# SAM9X60D1G_SOM device description
Architecture: ARM926EJ-S; Family: SAM9; Series: SAM9X6
Registers are 32-bit, read-write, no defined reset value unless marked. A register's access mark holds for its fields unless they carry their own. Offsets are from the block's base; [hi:lo] are bit positions; {n}, {i} and the like mark numbered series.

## AIC — Advanced Interrupt Controller
Instances: AIC 0xFFFFF100
0x00 AIC_SSR — Source Select Register
  [6:0] INTSEL — Interrupt Line Selection
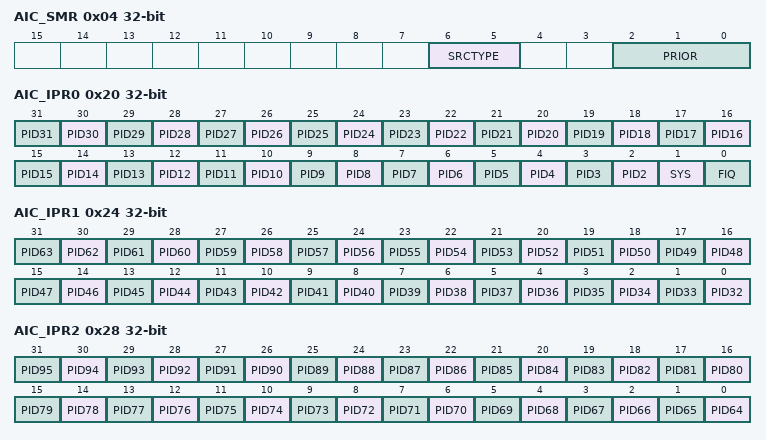
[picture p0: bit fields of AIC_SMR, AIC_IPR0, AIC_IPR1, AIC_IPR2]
0x04 AIC_SMR — Source Mode Register
  [6:5] SRCTYPE — Interrupt Source Type
    0=INT_LEVEL_SENSITIVE (High-level sensitive for internal source. Low-level sensitive for external source); 1=EXT_NEGATIVE_EDGE (Negative-edge triggered for external source); 2=EXT_HIGH_LEVEL (High-level sensitive for internal source. High-level sensitive for external source); 3=EXT_POSITIVE_EDGE (Positive-edge triggered for external source)
  [2:0] PRIOR — Priority Level
    0=MINIMUM (Minimum priority); 1=VERY_LOW (Very low priority); 2=LOW (Low priority); 3=MEDIUM_LOW (Medium priority); 4=MEDIUM_HIGH (Medium-high priority); 5=HIGH (High priority); 6=VERY_HIGH (Very high priority); 7=MAXIMUM (Maximum priority)
0x08 AIC_SVR — Source Vector Register
  [31:0] VECTOR — Source Vector
0x10 AIC_IVR ro — Interrupt Vector Register
  [31:0] IRQV
0x14 AIC_FVR ro — FIQ Vector Register
  [31:0] FIQV
0x18 AIC_ISR ro — Interrupt Status Register
  [6:0] IRQID — Current Interrupt Identifier
0x20 AIC_IPR0 ro — Interrupt Pending Register 0
  [n] PID{n} (n=2..31) — Interrupt Pending
  [1] SYS — Interrupt Pending
  [0] FIQ — Interrupt Pending
0x24 AIC_IPR1 ro — Interrupt Pending Register 1
  [n-32] PID{n} (n=32..63) — Interrupt Pending
0x28 AIC_IPR2 ro — Interrupt Pending Register 2
  [n-64] PID{n} (n=64..95) — Interrupt Pending
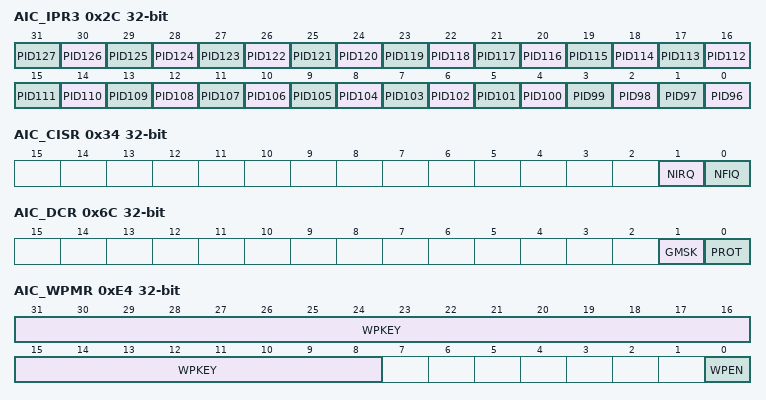
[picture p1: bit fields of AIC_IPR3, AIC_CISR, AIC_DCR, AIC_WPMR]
0x2C AIC_IPR3 ro — Interrupt Pending Register 3
  [n-96] PID{n} (n=96..127) — Interrupt Pending
0x30 AIC_IMR ro — Interrupt Mask Register
  [0] INTM — Interrupt Mask
0x34 AIC_CISR ro — Core Interrupt Status Register
  [1] NIRQ — NIRQ Status
  [0] NFIQ — NFIQ Status
0x38 AIC_EOICR wo — End of Interrupt Command Register
  [0] ENDIT — Interrupt Processing Complete Command
0x3C AIC_SPU — Spurious Interrupt Vector Register
  [31:0] SIVR
0x40 AIC_IECR wo — Interrupt Enable Command Register
  [0] INTEN — Interrupt Enable
0x44 AIC_IDCR wo — Interrupt Disable Command Register
  [0] INTD — Interrupt Disable
0x48 AIC_ICCR wo — Interrupt Clear Command Register
  [0] INTCLR — Interrupt Clear
0x4C AIC_ISCR wo — Interrupt Set Command Register
  [0] INTSET — Interrupt Set
0x50 AIC_FFER wo — Fast Forcing Enable Register
  [0] FFEN — Fast Forcing Enable
0x54 AIC_FFDR wo — Fast Forcing Disable Register
  [0] FFDIS — Fast Forcing Disable
0x58 AIC_FFSR ro — Fast Forcing Status Register
  [0] FFS — Fast Forcing Status
0x60 AIC_SVRRER wo — SVR Return Enable Register
  [0] SVRREN — SVR Return Enable
0x64 AIC_SVRRDR wo — SVR Return Disable Register
  [0] SVRRDIS — SVR Return Disable
0x68 AIC_SVRRSR ro — SVR Return Status Register
  [0] SVRRS — SVR Return Status
0x6C AIC_DCR — Debug Control Register
  [1] GMSK — General Interrupt Mask
  [0] PROT — Protection Mode
0xE4 AIC_WPMR — Write Protection Mode Register
  [31:8] WPKEY — Write Protection Key
    0x414943=PASSWD (Writing any other value in this field aborts the write operation of the WPEN bit. Always reads as 0.)
  [0] WPEN — Write Protection Enable
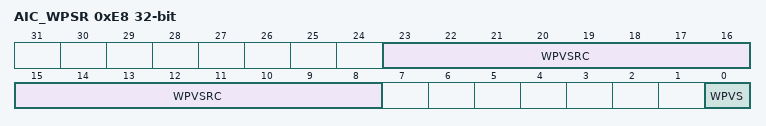
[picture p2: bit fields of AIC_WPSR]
0xE8 AIC_WPSR ro — Write Protection Status Register
  [23:8] WPVSRC — Write Protection Violation Source
  [0] WPVS — Write Protection Violation Status

## BSC — Boot Sequence Controller
Instances: BSC 0xFFFFFE54
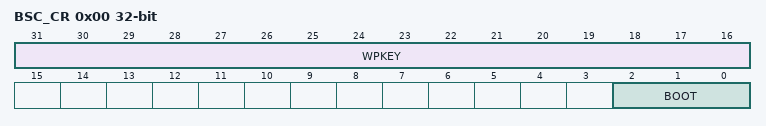
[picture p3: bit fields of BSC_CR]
0x00 BSC_CR — Boot Sequence Controller Configuration Register
  [31:16] WPKEY — Write Protection Key (Write-only)
    0x6683=PASSWD (Writing any other value in this field aborts the write operation of the BOOT field. Always reads as 0.)
  [2:0] BOOT — Boot Media Sequence

## CLASSD — Audio Class D Amplifier
Instances: CLASSD 0xF003C000
0x00 CLASSD_CR wo — Control Register
  [0] SWRST — Software Reset
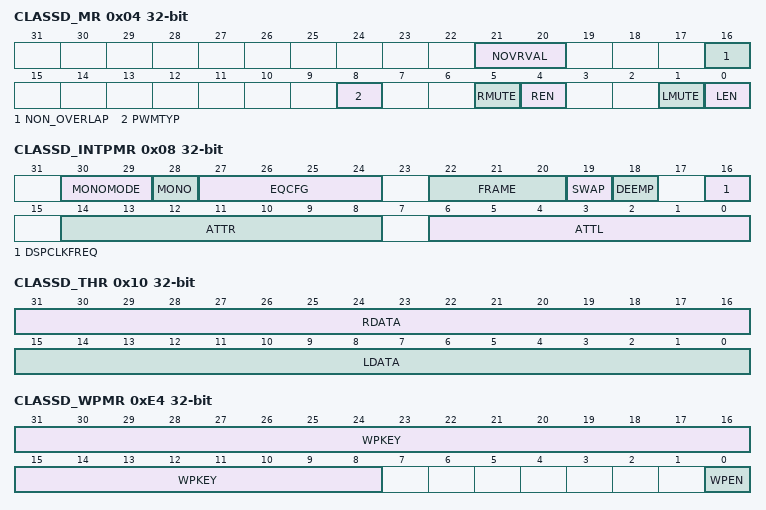
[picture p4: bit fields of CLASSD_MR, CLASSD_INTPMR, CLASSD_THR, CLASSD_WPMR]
0x04 CLASSD_MR — Mode Register
  [21:20] NOVRVAL — Non-Overlapping Value
    0=_5NS (Non-overlapping time is 5 ns); 1=_10NS (Non-overlapping time is 10 ns); 2=_15NS (Non-overlapping time is 15 ns); 3=_20NS (Non-overlapping time is 20 ns)
  [16] NON_OVERLAP — Non-Overlapping Enable
  [8] PWMTYP — PWM Modulation Type
    0=TRAILING_EDGE (The signal is single-ended.); 1=UNIFORM (The signal is differential.)
  [5] RMUTE — Right Channel Mute
  [4] REN — Right Channel Enable
  [1] LMUTE — Left Channel Mute
  [0] LEN — Left Channel Enable
0x08 CLASSD_INTPMR — Interpolator Mode Register
  [30:29] MONOMODE — Mono Mode Selection
    0=MONOMIX ((left + right) / 2 is sent on both channels); 1=MONOSAT ((left + right) is sent to both channels. If the sum is too high, the result is saturated.); 2=MONOLEFT (THR[15:0] is sent on both left and right channels); 3=MONORIGHT (THR[31:16] is sent on both left and right channels)
  [28] MONO — Mono Signal
    0=DISABLED (The signal is sent stereo to the left and right channels.); 1=ENABLED (The same signal is sent on both left and right channels. The sent signal is defined by the MONOMODE field value.)
  [27:24] EQCFG — Equalization Selection
    0=FLAT (Flat Response); 1=BBOOST12 (Bass boost +12 dB); 2=BBOOST6 (Bass boost +6 dB); 3=BCUT12 (Bass cut -12 dB); 4=BCUT6 (Bass cut -6 dB); 5=MBOOST3 (Medium boost +3 dB); 6=MBOOST8 (Medium boost +8 dB); 7=MCUT3 (Medium cut -3 dB); 8=MCUT8 (Medium cut -8 dB); 9=TBOOST12 (Treble boost +12 dB); 10=TBOOST6 (Treble boost +6 dB); 11=TCUT12 (Treble cut -12 dB); 12=TCUT6 (Treble cut -6 dB)
  [22:20] FRAME — CLASSD Incoming Data Sampling Frequency
    0=FRAME_8K (8 kHz); 1=FRAME_16K (16 kHz); 2=FRAME_32K (32 kHz); 3=FRAME_48K (48 kHz); 4=FRAME_96K (96 kHz); 5=FRAME_22K (22.05 kHz); 6=FRAME_44K (44.1 kHz); 7=FRAME_88K (88.2 kHz)
  [19] SWAP — Swap Left and Right Channels
    0=LEFT_ON_LSB (Left channel is on CLASSD_THR[15:0], right channel is on CLASSD_THR[31:16].); 1=RIGHT_ON_LSB (Right channel is on CLASSD_THR[15:0], left channel is on CLASSD_THR[31:16].)
  [18] DEEMP — Enable De-emphasis Filter
    0=DISABLED (De-emphasis filter is disabled.); 1=ENABLED (De-emphasis filter is enabled.)
  [16] DSPCLKFREQ — DSP Clock Frequency
    0=_12M288 (DSP Clock (DSPCLK) is 12.288 MHz.); 1=_11M2896 (DSP Clock (DSPCLK) is 11.2896 MHz.)
  [14:8] ATTR — Right Channel Attenuation
  [6:0] ATTL — Left Channel Attenuation
0x0C CLASSD_INTSR ro — Interpolator Status Register
  [0] CFGERR — Configuration Error
0x10 CLASSD_THR — Transmit Holding Register
  [31:16] RDATA — Right Channel Data
  [15:0] LDATA — Left Channel Data
0x14 CLASSD_IER wo — Interrupt Enable Register
  [0] DATRDY — Data Ready
0x18 CLASSD_IDR wo — Interrupt Disable Register
  [0] DATRDY — Data Ready
0x1C CLASSD_IMR — Interrupt Mask Register
  [0] DATRDY — Data Ready
0x20 CLASSD_ISR ro — Interrupt Status Register
  [0] DATRDY — Data Ready
0xE4 CLASSD_WPMR — Write Protection Mode Register
  [31:8] WPKEY — Write Protection Key
    0x434C44=PASSWD (Writing any other value in this field aborts the write operation of the WPEN bit. Always reads as 0.)
  [0] WPEN — Write Protection Enable

## Notices in the file
Copyright (c) 2019 Microchip Technology Inc.
SPDX-License-Identifier: Apache-2.0
Licensed under the Apache License, Version 2.0 (the "License");
you may not use this file except in compliance with the License.
You may obtain a copy of the License at
http://www.apache.org/licenses/LICENSE-2.0
Unless required by applicable law or agreed to in writing, software
distributed under the License is distributed on an "AS IS" BASIS,
WITHOUT WARRANTIES OR CONDITIONS OF ANY KIND, either express or implied.
See the License for the specific language governing permissions and
limitations under the License.
